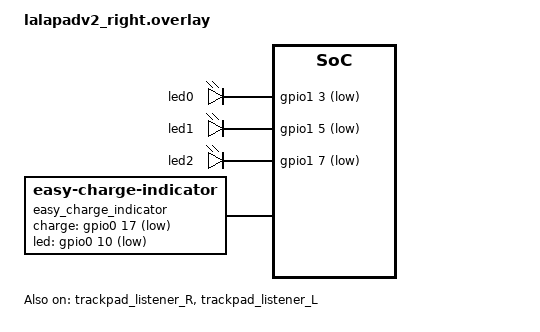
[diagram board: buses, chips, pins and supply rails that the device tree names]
#include "lalapadv2.dtsi"


/ {
    aliases {
        led-red = &led0;
        led-green = &led1;
        led-blue = &led2;
    };

    leds {
        compatible = "gpio-leds";
        status = "okay";
        led0: led_0 {
            gpios = <&gpio1 3 GPIO_ACTIVE_LOW>;  // red LED, connected to P1.03
        };
        led1: led_1 {
            gpios = <&gpio1 5 GPIO_ACTIVE_LOW>;  // green LED, connected to P1.05
        };
        led2: led_2 {
            gpios = <&gpio1 7 GPIO_ACTIVE_LOW>;  // blue LED, connected to P1.07
        };
    };
    
    easy_charge_indicator: easy_charge_indicator {
        compatible = "zmk,easy-charge-indicator";
        status = "okay";
        charge-gpios = <&gpio0 17 GPIO_ACTIVE_LOW>;
        led-gpios = <&gpio0 10 (GPIO_ACTIVE_LOW | GPIO_OPEN_DRAIN)>;
   };
};

&default_transform {
    col-offset = <6>;
};

&kscan0 {
    col-gpios
        = <&xiao_d 0 GPIO_ACTIVE_HIGH>
        , <&xiao_d 1 GPIO_ACTIVE_HIGH>
        , <&xiao_d 2 GPIO_ACTIVE_HIGH>
        , <&xiao_d 3 GPIO_ACTIVE_HIGH>
        , <&gpio0 15 GPIO_ACTIVE_HIGH>
        , <&gpio0 19 GPIO_ACTIVE_HIGH>
        ;
};


&trackpad_listener_R {
    status = "okay";
    device = <&iqs9151>;
};
&trackpad_listener_L {
    status = "okay";
};
